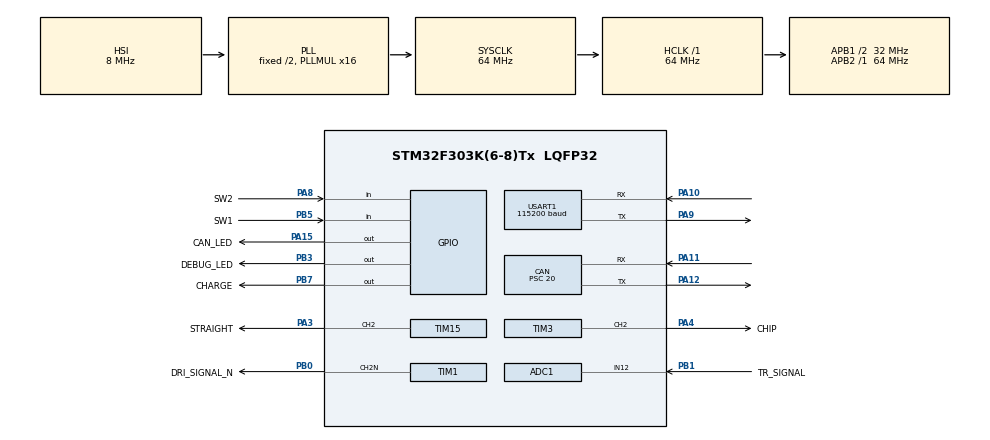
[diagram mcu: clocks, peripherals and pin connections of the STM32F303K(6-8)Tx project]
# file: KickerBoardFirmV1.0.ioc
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ADC1.Channel-1\#ChannelRegularConversion=ADC_CHANNEL_12
ADC1.NbrOfConversionFlag=1
ADC1.Offset-1\#ChannelRegularConversion=0
ADC1.OffsetNumber-1\#ChannelRegularConversion=ADC_OFFSET_NONE
ADC1.Rank-1\#ChannelRegularConversion=1
ADC1.SamplingTime-1\#ChannelRegularConversion=ADC_SAMPLETIME_19CYCLES_5
ADC1.SamplingTimeOPAMP-1\#ChannelRegularConversion=ADC_SAMPLETIME_61CYCLES_5
ADC1.SubFamily=STM32F303x8
ADC1.master=1
CAN.BS1=CAN_BS1_13TQ
CAN.BS2=CAN_BS2_2TQ
CAN.CalculateBaudRate=100000
CAN.CalculateTimeBit=10000
CAN.CalculateTimeQuantum=625.0
CAN.Prescaler=20
Dma.Request0=USART1_TX
Dma.Request1=USART1_RX
Dma.USART1_RX.1.Direction=DMA_PERIPH_TO_MEMORY
Dma.USART1_RX.1.Instance=DMA1_Channel5
Dma.USART1_RX.1.MemDataAlignment=DMA_MDATAALIGN_BYTE
Dma.USART1_RX.1.MemInc=DMA_MINC_ENABLE
Dma.USART1_RX.1.Mode=DMA_CIRCULAR
Dma.USART1_RX.1.PeriphDataAlignment=DMA_PDATAALIGN_BYTE
Dma.USART1_RX.1.PeriphInc=DMA_PINC_DISABLE
Dma.USART1_RX.1.Priority=DMA_PRIORITY_LOW
Dma.USART1_TX.0.Direction=DMA_MEMORY_TO_PERIPH
Dma.USART1_TX.0.Instance=DMA1_Channel4
Dma.USART1_TX.0.MemDataAlignment=DMA_MDATAALIGN_BYTE
Dma.USART1_TX.0.MemInc=DMA_MINC_ENABLE
Dma.USART1_TX.0.Mode=DMA_NORMAL
Dma.USART1_TX.0.PeriphDataAlignment=DMA_PDATAALIGN_BYTE
Dma.USART1_TX.0.PeriphInc=DMA_PINC_DISABLE
Dma.USART1_TX.0.Priority=DMA_PRIORITY_LOW
Mcu.Family=STM32F3
Mcu.Name=STM32F303K(6-8)Tx
Mcu.Package=LQFP32
NVIC.CAN_RX0_IRQn=true\:0\:0\:false\:false\:true\:true\:true\:true
NVIC.CAN_RX1_IRQn=true\:0\:0\:false\:false\:true\:true\:true\:true
NVIC.CAN_TX_IRQn=true\:0\:0\:false\:false\:true\:true\:true\:true
NVIC.DMA1_Channel4_IRQn=true\:0\:0\:false\:false\:true\:false\:true\:true
NVIC.DMA1_Channel5_IRQn=true\:0\:0\:false\:false\:true\:false\:true\:true
NVIC.PriorityGroup=NVIC_PRIORITYGROUP_4
NVIC.USART1_IRQn=true\:0\:0\:false\:false\:true\:true\:true\:true
PA10.Mode=Asynchronous
PA10.Signal=USART1_RX
PA11.Mode=CAN_Activate
PA11.Signal=CAN_RX
PA12.Mode=CAN_Activate
PA12.Signal=CAN_TX
PA13.GPIO_Label=SWDIO
PA13.Mode=Serial_Wire
PA13.Signal=SYS_JTMS-SWDIO
PA14.GPIO_Label=SWCLK
PA14.Mode=Serial_Wire
PA14.Signal=SYS_JTCK-SWCLK
PA15.GPIO_Label=CAN_LED
PA15.Signal=GPIO_Output
PA3.GPIO_Label=STRAIGHT
PA3.Signal=S_TIM15_CH2
PA4.GPIO_Label=CHIP
PA4.Signal=S_TIM3_CH2
PA8.GPIO_Label=SW2
PA8.Signal=GPIO_Input
PA9.Mode=Asynchronous
PA9.Signal=USART1_TX
PB0.GPIO_Label=DRI_SIGNAL_N
PB0.Mode=PWM Generation2 CH2N
PB0.Signal=TIM1_CH2N
PB1.GPIO_Label=TR_SIGNAL
PB1.Mode=IN12-Single-Ended
PB1.Signal=ADC1_IN12
PB3.GPIO_Label=DEBUG_LED
PB3.Signal=GPIO_Output
PB5.GPIO_Label=SW1
PB5.Signal=GPIO_Input
PB7.GPIO_Label=CHARGE
PB7.Signal=GPIO_Output
ProjectManager.HeapSize=0x200
ProjectManager.StackSize=0x400
ProjectManager.TargetToolchain=Makefile
RCC.AHBFreq_Value=64000000
RCC.APB1CLKDivider=RCC_HCLK_DIV2
RCC.APB1Freq_Value=32000000
RCC.APB1TimFreq_Value=64000000
RCC.APB2Freq_Value=64000000
RCC.APB2TimFreq_Value=64000000
RCC.CortexFreq_Value=64000000
RCC.HCLKFreq_Value=64000000
RCC.HSE_VALUE=8000000
RCC.HSI_VALUE=8000000
RCC.PLLMUL=RCC_PLL_MUL16
RCC.SYSCLKFreq_VALUE=64000000
RCC.SYSCLKSourceVirtual=RCC_SYSCLKSOURCE_PLLCLK
SH.S_TIM15_CH2.0=TIM15_CH2,PWM Generation2 CH2
SH.S_TIM3_CH2.0=TIM3_CH2,PWM Generation2 CH2
TIM1.Channel-PWM\ Generation2\ CH2N=TIM_CHANNEL_2
TIM1.Period=999
TIM1.Prescaler=1279
TIM15.Channel-PWM\ Generation2\ CH2=TIM_CHANNEL_2
TIM15.Period=999
TIM15.Prescaler=127
TIM3.Channel-PWM\ Generation2\ CH2=TIM_CHANNEL_2
TIM3.Period=999
TIM3.Prescaler=128
TIM6.Period=100
TIM6.Prescaler=64000
USART1.BaudRate=115200
USART1.VirtualMode-Asynchronous=VM_ASYNC
VP_TIM6_VS_ClockSourceINT.Mode=Enable_Timer
board=NUCLEO-F303K8

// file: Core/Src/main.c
/* USER CODE BEGIN Header */
/**
 ******************************************************************************
 * @file           : main.c
 * @brief          : Main program body
 ******************************************************************************
 * @attention
 *
 * Copyright (c) 2024 STMicroelectronics.
 * All rights reserved.
 *
 * This software is licensed under terms that can be found in the LICENSE file
 * in the root directory of this software component.
 * If no LICENSE file comes with this software, it is provided AS-IS.
 *
 ******************************************************************************
 */
/* USER CODE END Header */
#include "main.h"
#include "adc.h"
#include "can.h"
#include "dma.h"
#include "tim.h"
#include "usart.h"
#include "gpio.h"

/* USER CODE BEGIN Includes */
#include "app.h"
/* USER CODE END Includes */

void SystemClock_Config(void);

/* USER CODE BEGIN 0 */
CAN_TxHeaderTypeDef TxHeader;
CAN_RxHeaderTypeDef RxHeader;

uint8_t TxData[8];
uint8_t RxData[8];

uint32_t TxMailbox;
/* USER CODE END 0 */

int main(void)
{

  /* MCU Configuration--------------------------------------------------------*/

  /* Reset of all peripherals, Initializes the Flash interface and the Systick. */
  HAL_Init();

  /* Configure the system clock */
  SystemClock_Config();

  /* Initialize all configured peripherals */
  MX_GPIO_Init();
  MX_DMA_Init();
  MX_ADC1_Init();
  MX_CAN_Init();
  MX_TIM1_Init();
  MX_TIM15_Init();
  MX_USART1_UART_Init();
  MX_TIM6_Init();
  MX_TIM3_Init();

  /* Infinite loop */
  /* USER CODE BEGIN WHILE */
    main_app();
    while (1) {
    /* USER CODE END WHILE */

    }
}

void SystemClock_Config(void)
{
  RCC_OscInitTypeDef RCC_OscInitStruct = {0};
  RCC_ClkInitTypeDef RCC_ClkInitStruct = {0};
  RCC_PeriphCLKInitTypeDef PeriphClkInit = {0};

  /** Initializes the RCC Oscillators according to the specified parameters
  * in the RCC_OscInitTypeDef structure.
  */
  RCC_OscInitStruct.OscillatorType = RCC_OSCILLATORTYPE_HSI;
  RCC_OscInitStruct.HSIState = RCC_HSI_ON;
  RCC_OscInitStruct.HSICalibrationValue = RCC_HSICALIBRATION_DEFAULT;
  RCC_OscInitStruct.PLL.PLLState = RCC_PLL_ON;
  RCC_OscInitStruct.PLL.PLLSource = RCC_PLLSOURCE_HSI;
  RCC_OscInitStruct.PLL.PLLMUL = RCC_PLL_MUL16;
  if (HAL_RCC_OscConfig(&RCC_OscInitStruct) != HAL_OK)
  {
    Error_Handler();
  }

  /** Initializes the CPU, AHB and APB buses clocks
  */
  RCC_ClkInitStruct.ClockType = RCC_CLOCKTYPE_HCLK|RCC_CLOCKTYPE_SYSCLK
                              |RCC_CLOCKTYPE_PCLK1|RCC_CLOCKTYPE_PCLK2;
  RCC_ClkInitStruct.SYSCLKSource = RCC_SYSCLKSOURCE_PLLCLK;
  RCC_ClkInitStruct.AHBCLKDivider = RCC_SYSCLK_DIV1;
  RCC_ClkInitStruct.APB1CLKDivider = RCC_HCLK_DIV2;
  RCC_ClkInitStruct.APB2CLKDivider = RCC_HCLK_DIV1;

  if (HAL_RCC_ClockConfig(&RCC_ClkInitStruct, FLASH_LATENCY_2) != HAL_OK)
  {
    Error_Handler();
  }
  PeriphClkInit.PeriphClockSelection = RCC_PERIPHCLK_USART1|RCC_PERIPHCLK_TIM1
                              |RCC_PERIPHCLK_ADC12;
  PeriphClkInit.Usart1ClockSelection = RCC_USART1CLKSOURCE_PCLK1;
  PeriphClkInit.Adc12ClockSelection = RCC_ADC12PLLCLK_DIV1;
  PeriphClkInit.Tim1ClockSelection = RCC_TIM1CLK_HCLK;
  if (HAL_RCCEx_PeriphCLKConfig(&PeriphClkInit) != HAL_OK)
  {
    Error_Handler();
  }
}

void Error_Handler(void)
{
    __disable_irq();
    while (1) {
    }
}
